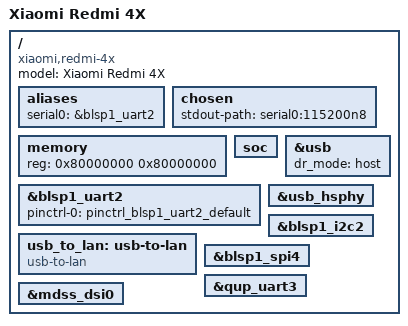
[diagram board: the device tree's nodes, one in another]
/dts-v1/;

#include "msm8917.dtsi"
// #include "qcom-msm89xx-common.dtsi" (tidak tersedia, akan digantikan manual jika perlu)

/ {
    model = "Xiaomi Redmi 4X";
    compatible = "xiaomi,redmi-4x", "qcom,msm8917";

    aliases {
        serial0 = &blsp1_uart2;
    };

    chosen {
        stdout-path = "serial0:115200n8";
    };

    memory {
        device_type = "memory";
        reg = <0x80000000 0x80000000>; // 2GB RAM
    };

    soc {
        // Tambahkan node hardware spesifik jika diperlukan
    };

    /* Modem LTE Internal */
    &blsp1_uart2 {
        status = "okay";
        pinctrl-names = "default";
        pinctrl-0 = <&pinctrl_blsp1_uart2_default>;
    };

    &usb {
        status = "okay";
        dr_mode = "host"; // Aktifkan mode USB host untuk USB-to-LAN
    };

    &usb_hsphy {
        status = "okay";
    };

    /* Dukungan USB-to-LAN Gigabit */
    usb_to_lan: usb-to-lan {
        compatible = "usb-to-lan";
        status = "okay";
    };

    /* Tambahan dari output.dts */
    &blsp1_i2c2 {
        status = "okay";
    };

    &blsp1_spi4 {
        status = "okay";
    };

    &qup_uart3 {
        status = "okay";
    };

    &mdss_dsi0 {
        status = "okay";
    };
};

// Tambahkan lebih banyak detail berdasarkan output.dts dan msm8917.dtsi
